# ISD9100_v3 register map
File version: 1.0
Registers are 32-bit, read-write, reset 0x0 unless marked. A register's access mark holds for its fields unless they carry their own. Offsets are from the block's base; [hi:lo] are bit positions; {n}, {i} and the like mark numbered series.

## SYS — SYS Register Map
Base 0x50000000
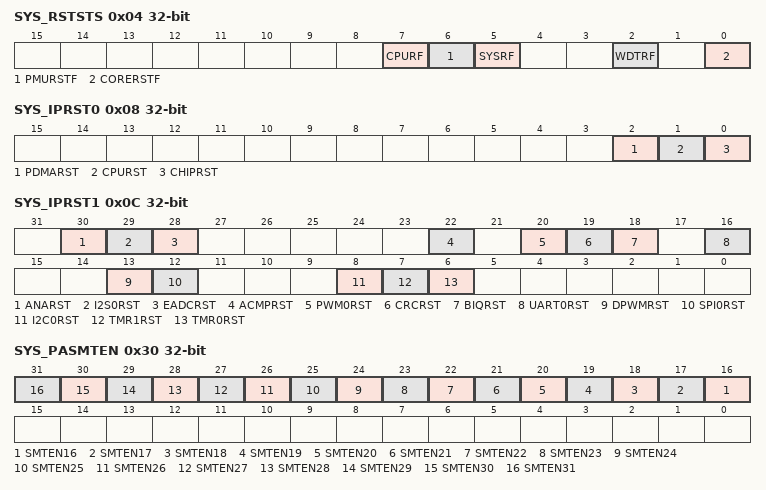
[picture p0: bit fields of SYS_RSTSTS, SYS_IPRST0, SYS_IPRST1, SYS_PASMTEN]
0x04 SYS_RSTSTS (reset mask 0xFFFFFF00) — System Reset Source Register
  [7] CPURF — Reset Source From CPU. The CPURF flag is set by hardware if software writes SYS_IPRST0.CPURST with a "1" to reset Cortex-M0 CPU kernel and Flash memory controller (FMC). This bit is cleared by writing 1 to itself.
    0=No reset from CPU; 1=The Cortex-M0 CPU kernel and FMC has been reset by software setting CPURST to 1
  [6] PMURSTF — Reset Source From PMU. The PMURSTF flag is set if the PMU. This bit is cleared by writing 1 to itself.
    0=No reset from PMU; 1=PMU reset the system from a power down/standby event
  [5] SYSRF — Reset Source From MCU. The SYSRF flag is set if the previous reset source originates from the Cortex_M0 kernel. This bit is cleared by writing 1 to itself.
    0=No reset from MCU; 1=The Cortex_M0 MCU issued a reset signal to reset the system by software writing 1 to bit SYSCTL_AIRCTL.SYSRESTREQ, Application Interrupt and Reset Control Register) in system control registers of Cortex_M0 kernel
  [2] WDTRF — Reset Source From WDT. The WDTRF flag is set if pervious reset source originates from the Watch-Dog module. This bit is cleared by writing 1 to itself.
    0=No reset from Watch-Dog; 1=The Watch-Dog module issued the reset signal to reset the system
  [0] CORERSTF — Reset Source From CORE. The CORERSTF flag is set if the core has been reset. Possible sources of reset are a Power-On Reset (POR), RESETn Pin Reset or PMU reset. This bit is cleared by writing 1 to itself.
    0=No reset from CORE; 1=Core was reset by hardware block
0x08 SYS_IPRST0 — IP Reset Control Resister1
  [2] PDMARST — PDMA Controller Reset. Set "1" will generate a reset signal to the PDMA Block. User needs to set this bit to "0" to release from the reset state
    0=Normal operation; 1=PDMA IP reset
  [1] CPURST — CPU Kernel One Shot Reset. Setting this bit will reset the CPU kernel and Flash Memory Controller(FMC), this bit will automatically return to "0" after the 2 clock cycles. This bit is a protected bit, to program first issue the unlock sequence (see Protected Register Lock Key Register (SYS_REGLCTL))
    0=Normal; 1=Reset CPU
  [0] CHIPRST — CHIP One Shot Reset. Set this bit will reset the whole chip, this bit will automatically return to "0" after the 2 clock cycles. CHIPRST has same behavior as POR reset, all the chip modules are reset and the chip configuration settings from flash are reloaded. This bit is a protected bit, to program first issue the unlock sequence (see Protected Register Lock Key Register (SYS_REGLCTL))
    0=Normal; 1=Reset CHIP
0x0C SYS_IPRST1 — IP Reset Control Resister2
  [all] fields
    0=Normal Operation; 1=Reset
  [30] ANARST — Analog Block Control Reset
  [29] I2S0RST — I2S Controller Reset
  [28] EADCRST — ADC Controller Reset
  [22] ACMPRST — Analog Comparator Reset
  [20] PWM0RST — PWM10 controller Reset
  [19] CRCRST — CRC Generation Block Reset
  [18] BIQRST — Biquad Filter Block Reset
  [16] UART0RST — UART0 Controller Reset
  [13] DPWMRST — DPWM Speaker Driver Reset
  [12] SPI0RST — SPI0 Controller Reset
  [8] I2C0RST — I2C0 Controller Reset
  [7] TMR1RST — Timer1 Controller Reset
  [6] TMR0RST — Timer0 Controller Reset
0x30 SYS_PASMTEN — GPIOA input type control register
  [all] fields
    0=GPIOA[15:0] I/O input Schmitt Trigger disabled; 1=GPIOA[15:0] I/O input Schmitt Trigger enabled
  [n] SMTEN{n} (n=16..31) — Schmitt Trigger. This register controls whether the GPIO input buffer Schmitt trigger is enabled.
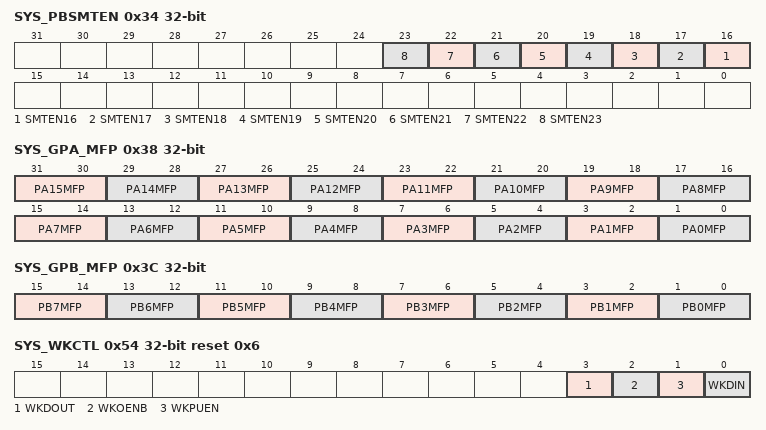
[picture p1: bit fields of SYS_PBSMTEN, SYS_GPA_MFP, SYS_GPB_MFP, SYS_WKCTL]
0x34 SYS_PBSMTEN — GPIOB input type control register
  [all] fields
    0=GPIOB(port 0 ~ port 7) I/O input Schmitt Trigger disabled; 1=GPIOB(port 0 ~ port 7) I/O input Schmitt Trigger enabled
  [n] SMTEN{n} (n=16..23) — Schmitt Trigger. This register controls whether the GPIO input buffer Schmitt trigger is enabled.
0x38 SYS_GPA_MFP — GPIOA multiple function control register
  [31:30] PA15MFP — Alternate Function Setting For PA15MFP
    0=GPIO; 1=TM1; 2=SDIN
  [29:28] PA14MFP — Alternate Function Setting For PA14MFP
    0=GPIO; 1=TM0; 2=SDCLK; 3=SDCLKn
  [27:26] PA13MFP — Alternate Function Setting For PA13MFP
    0=GPIO; 1=PWM1; 2=SPKM; 3=I2S_BCLK
  [25:24] PA12MFP — Alternate Function Setting For PA12MFP
    0=GPIO; 1=PWM0; 2=SPKP; 3=I2S_FS
  [23:22] PA11MFP — Alternate Function Setting For PA11MFP
    0=GPIO; 1=I2C_SCL; 2=I2S_SDO; 3=UART_CTSn
  [21:20] PA10MFP — Alternate Function Setting For PA10MFP
    0=GPIO; 1=I2C_SDA; 2=I2S_SDI; 3=UART_RTSn
  [19:18] PA9MFP — Alternate Function Setting For PA0MFP
    0=GPIO; 1=UART_RX; 2=I2S_BCLK
  [17:16] PA8MFP — Alternate Function Setting For PA8MFP
    0=GPIO; 1=UART_TX; 2=I2S_FS
  [15:14] PA7MFP — Alternate Function Setting For PA7MFP
    0=GPIO; 1=I2S_SDO
  [13:12] PA6MFP — Alternate Function Setting For PA6MFP
    0=GPIO; 1=I2S_SDI
  [11:10] PA5MFP — Alternate Function Setting For PA5MFP
    0=GPIO; 1=I2S_BCLK
  [9:8] PA4MFP — Alternate Function Setting For PA4MFP
    0=GPIO; 1=I2S_FS
  [7:6] PA3MFP — Alternate Function Setting For PA3MFP
    0=GPIO; 1=SPI_MISO0; 2=I2C_SDA
  [5:4] PA2MFP — Alternate Function Setting For PA2MFP
    0=GPIO; 1=SPI_SSB0
  [3:2] PA1MFP — Alternate Function Setting For PA1MFP
    0=GPIO; 1=SPI_SCLK; 2=I2C_SCL
  [1:0] PA0MFP — Alternate Function Setting For PA0MFP
    0=GPIO; 1=SPI_MOSI0; 2=MCLK
0x3C SYS_GPB_MFP — GPIOB multiple function control register
  [15:14] PB7MFP — Alternate Function Setting For PB7MFP
    0=GPIO; 1=I2S_SDO; 2=CMP7
  [13:12] PB6MFP — Alternate Function Setting For PB6MFP
    0=GPIO; 1=I2S_SDI; 2=CMP6; 3=SPI_MOSI1
  [11:10] PB5MFP — Alternate Function Setting For PB5MFP
    0=GPIO; 1=PWM1B; 2=CMP5; 3=SPI_MISO1
  [9:8] PB4MFP — Alternate Function Setting For PB4MFP
    0=GPIO; 1=PWM0B; 2=CMP4; 3=SPI_MOSI0
  [7:6] PB3MFP — Alternate Function Setting For PB3MFP
    0=GPIO; 1=I2C_SDA; 2=CMP3; 3=SPI_MISO0
  [5:4] PB2MFP — Alternate Function Setting For PB2MFP
    0=GPIO; 1=I2C_SCL; 2=CMP2; 3=SPI_SCLK
  [3:2] PB1MFP — Alternate Function Setting For PB1MFP
    0=GPIO; 1=MCLK; 2=CMP1; 3=SPI_SSB1
  [1:0] PB0MFP — Alternate Function Setting For PB0MFP
    0=GPIO; 1=SPI_SSB1; 2=CMP0; 3=SPI_SSB0
0x54 SYS_WKCTL reset 0x6 — WAKEUP pin control register
  [3] WKDOUT — Wakeup Output State
    0=drive Low if the corresponding output mode bit is set (default); 1=drive High if the corresponding output mode bit is set
  [2] WKOENB — Wakeup Pin Output Enable Bar
    0=drive WKDOUT to pin; 1=tristate (default)
  [1] WKPUEN — Wakeup Pin Pull-up Control. This signal is latched in deep power down and preserved.
    0=pull-up enable; 1=tristate (default)
  [0] WKDIN — State Of Wakeup Pin. Read only.
0x100 SYS_REGLCTL — Register Lock Key Address register
  [0] REGLCTL — Protected Register Unlock Register
    0=Protected registers are locked. Any write to the target register is ignored; 1=Protected registers are unlocked
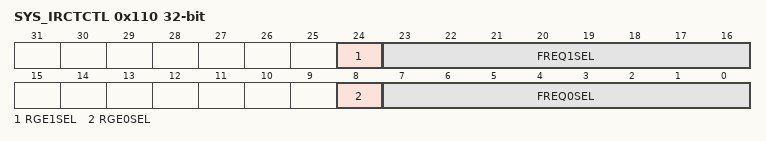
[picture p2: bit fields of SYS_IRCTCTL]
0x110 SYS_IRCTCTL reset not defined — Oscillator Frequency Adjustment control register
  [24] RGE1SEL — Range Bit For Oscillator
    0=high range; 1=low range
  [23:16] FREQ1SEL — 8 Bit Trim For Oscillator. FREQ1SEL [7:5] are 8 coarse trim ranges which overlap in frequency. FREQ1SEL [4:0] are 32 fine trim steps of approximately 0.5% resolution.
  [8] RGE0SEL — Range Bit For Oscillator
    0=high range; 1=low range
  [7:0] FREQ0SEL — 8 Bit Trim For Oscillator. FREQ0SEL [7:5] are 8 coarse trim ranges which overlap in frequency. FREQ0SEL [4:0] are 32 fine trim steps of approximately 0.5% resolution.
